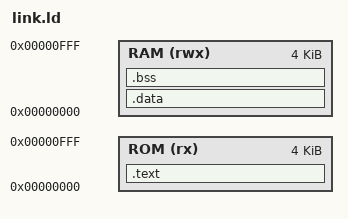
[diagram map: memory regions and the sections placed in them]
OUTPUT_ARCH("riscv")
ENTRY(_start)

MEMORY
{
    ROM (rx)  : ORIGIN = 0x00000000, LENGTH = 4K
    RAM (rwx) : ORIGIN = 0x00000000, LENGTH = 4K
}

SECTIONS
{
    .text : {
        *(.text._start)
        *(.text*)
        *(.rodata*)
    } > ROM

    .data : {
        *(.data*)
        *(.sdata*)
    } > RAM

    .bss : {
        *(.bss*)
        *(.sbss*)
    } > RAM

    _stack_top = ORIGIN(RAM) + LENGTH(RAM);
}
